VERSION "HSCAN2"

NS_ :

BS_:

BU_: FVCM GW Diagnostics EPS SCSABS Tester

BO_ 1947 DIAG_DTCInfo_FVCM: 7 FVCM
 SG_ DTCInfomationFVCMHSC2 : 7|56@0+ (1,0) [0|0] ""  GW

BO_ 1851 DIAG_PhysResp_FVCM: 8 FVCM
 SG_ DiagnosticRespFVCM : 7|64@0+ (1,0) [0|0] ""  Diagnostics

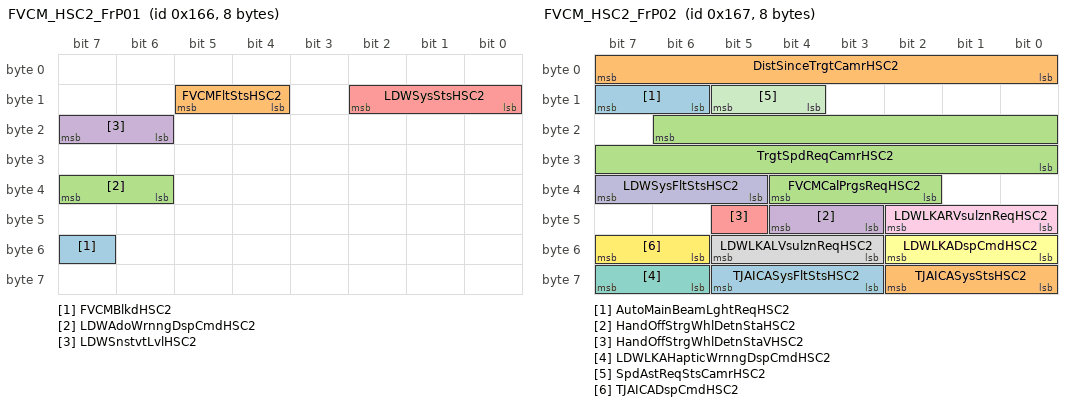
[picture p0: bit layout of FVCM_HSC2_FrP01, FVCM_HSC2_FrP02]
BO_ 358 FVCM_HSC2_FrP01: 8 FVCM
 SG_ FVCMBlkdHSC2 : 55|1@0+ (1,0) [0|1] ""  GW
 SG_ FVCMFltStsHSC2 : 13|2@0+ (1,0) [0|3] ""  GW,EPS
 SG_ LDWAdoWrnngDspCmdHSC2 : 39|2@0+ (1,0) [0|3] ""  GW
 SG_ LDWSnstvtLvlHSC2 : 23|2@0+ (1,0) [0|3] ""  GW
 SG_ LDWSysStsHSC2 : 10|3@0+ (1,0) [0|7] ""  GW

BO_ 359 FVCM_HSC2_FrP02: 8 FVCM
 SG_ AutoMainBeamLghtReqHSC2 : 15|2@0+ (1,0) [0|3] ""  GW
 SG_ DistSinceTrgtCamrHSC2 : 7|8@0+ (8.235,-100) [-100|1999.92] "m"  GW
 SG_ FVCMCalPrgsReqHSC2 : 36|3@0+ (1,0) [0|7] ""  GW
 SG_ HandOffStrgWhlDetnStaHSC2 : 44|2@0+ (1,0) [0|3] ""  GW
 SG_ HandOffStrgWhlDetnStaVHSC2 : 45|1@0+ (1,0) [0|1] ""  GW
 SG_ LDWLKADspCmdHSC2 : 50|3@0+ (1,0) [0|7] ""  GW
 SG_ LDWLKAHapticWrnngDspCmdHSC2 : 63|2@0+ (1,0) [0|3] ""  GW
 SG_ LDWLKALVsulznReqHSC2 : 53|3@0+ (1,0) [0|7] ""  GW
 SG_ LDWLKARVsulznReqHSC2 : 42|3@0+ (1,0) [0|7] ""  GW
 SG_ LDWSysFltStsHSC2 : 39|3@0+ (1,0) [0|7] ""  GW
 SG_ SpdAstReqStsCamrHSC2 : 13|2@0+ (1,0) [0|3] ""  GW
 SG_ TJAICADspCmdHSC2 : 55|2@0+ (1,0) [0|3] ""  GW
 SG_ TJAICASysFltStsHSC2 : 61|3@0+ (1,0) [0|7] ""  GW,EPS
 SG_ TJAICASysStsHSC2 : 58|3@0+ (1,0) [0|7] ""  GW,EPS
 SG_ TrgtSpdReqCamrHSC2 : 22|15@0+ (0.015625,0) [0|511.984] ""  GW

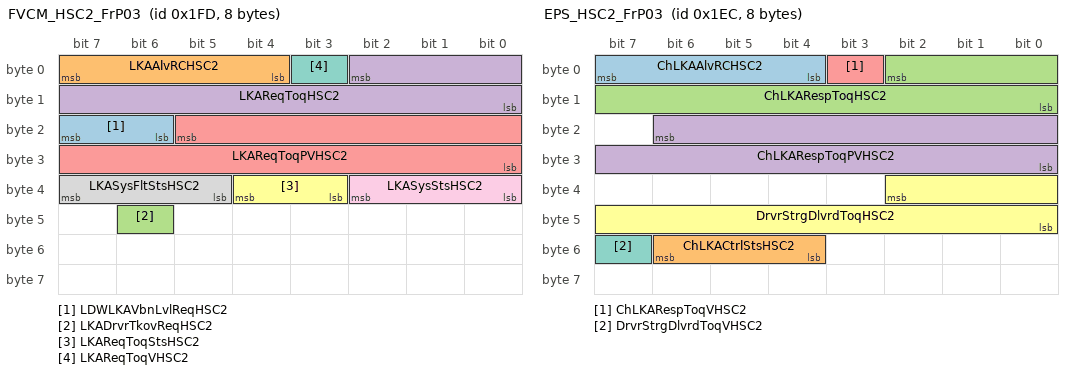
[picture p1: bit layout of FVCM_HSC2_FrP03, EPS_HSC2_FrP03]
BO_ 509 FVCM_HSC2_FrP03: 8 FVCM
 SG_ LDWLKAVbnLvlReqHSC2 : 23|2@0+ (1,0) [0|3] ""  GW,EPS
 SG_ LKAAlvRCHSC2 : 7|4@0+ (1,0) [0|15] ""  EPS
 SG_ LKADrvrTkovReqHSC2 : 46|1@0+ (1,0) [0|1] ""  GW,EPS
 SG_ LKAReqToqHSC2 : 2|11@0+ (0.01,-10.24) [-10.24|10.23] "Nm"  EPS
 SG_ LKAReqToqPVHSC2 : 21|14@0+ (1,0) [0|16383] ""  EPS
 SG_ LKAReqToqStsHSC2 : 36|2@0+ (1,0) [0|3] ""  EPS
 SG_ LKAReqToqVHSC2 : 3|1@0+ (1,0) [0|1] ""  EPS
 SG_ LKASysFltStsHSC2 : 39|3@0+ (1,0) [0|7] ""  GW,EPS
 SG_ LKASysStsHSC2 : 34|3@0+ (1,0) [0|7] ""  GW,EPS

BO_ 2015 DIAG_FuncReq_HSC2: 8 Diagnostics
 SG_ DiagnosticFuncAddrReq_h2 : 7|64@0+ (1,0) [0|0] ""  FVCM

BO_ 1843 DIAG_PhysReq_FVCM: 8 Diagnostics
 SG_ DiagnosticReqFVCM_h2 : 7|64@0+ (1,0) [0|0] ""  FVCM

BO_ 492 EPS_HSC2_FrP03: 8 EPS
 SG_ ChLKAAlvRCHSC2 : 7|4@0+ (1,0) [0|15] ""  FVCM
 SG_ ChLKACtrlStsHSC2 : 54|3@0+ (1,0) [0|7] ""  FVCM
 SG_ ChLKARespToqHSC2 : 2|11@0+ (0.01,-10.24) [-10.24|10.23] "Nm"  FVCM
 SG_ ChLKARespToqPVHSC2 : 22|15@0+ (1,0) [0|32767] ""  FVCM
 SG_ ChLKARespToqVHSC2 : 3|1@0+ (1,0) [0|1] ""  FVCM
 SG_ DrvrStrgDlvrdToqHSC2 : 34|11@0+ (0.01,-10.24) [-10.24|10.23] "Nm"  FVCM
 SG_ DrvrStrgDlvrdToqVHSC2 : 55|1@0+ (1,0) [0|1] ""  FVCM

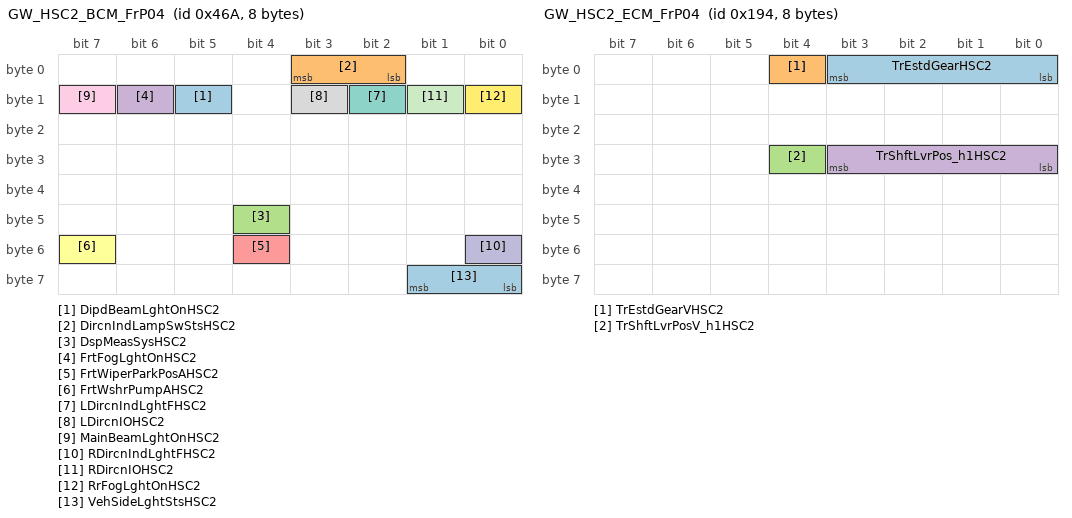
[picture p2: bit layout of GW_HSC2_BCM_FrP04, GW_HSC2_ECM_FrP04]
BO_ 1130 GW_HSC2_BCM_FrP04: 8 GW
 SG_ DipdBeamLghtOnHSC2 : 13|1@0+ (1,0) [0|1] ""  FVCM
 SG_ DircnIndLampSwStsHSC2 : 3|2@0+ (1,0) [0|3] ""  FVCM
 SG_ DspMeasSysHSC2 : 44|1@0+ (1,0) [0|1] ""  FVCM
 SG_ FrtFogLghtOnHSC2 : 14|1@0+ (1,0) [0|1] ""  FVCM
 SG_ FrtWiperParkPosAHSC2 : 52|1@0+ (1,0) [0|1] ""  FVCM
 SG_ FrtWshrPumpAHSC2 : 55|1@0+ (1,0) [0|1] ""  FVCM
 SG_ LDircnIndLghtFHSC2 : 10|1@0+ (1,0) [0|1] ""  FVCM
 SG_ LDircnIOHSC2 : 11|1@0+ (1,0) [0|1] ""  FVCM
 SG_ MainBeamLghtOnHSC2 : 15|1@0+ (1,0) [0|1] ""  FVCM
 SG_ RDircnIndLghtFHSC2 : 48|1@0+ (1,0) [0|1] ""  FVCM
 SG_ RDircnIOHSC2 : 9|1@0+ (1,0) [0|1] ""  FVCM
 SG_ RrFogLghtOnHSC2 : 8|1@0+ (1,0) [0|1] ""  FVCM
 SG_ VehSideLghtStsHSC2 : 57|2@0+ (1,0) [0|3] ""  FVCM

BO_ 540 GW_HSC2_BCM_FrP06: 8 GW
 SG_ ClstrDspdVehSpdHSC2 : 55|8@0+ (1,0) [0|254] "km/h"  FVCM
 SG_ FrtWiperSwStsHSC2 : 47|2@0+ (1,0) [0|3] ""  FVCM

BO_ 498 GW_HSC2_BCM_FrP07: 2 GW
 SG_ SysBPMHSC2 : 5|2@0+ (1,0) [0|3] ""  FVCM
 SG_ SysBPMEnbdHSC2 : 6|1@0+ (1,0) [0|1] ""  FVCM

BO_ 404 GW_HSC2_ECM_FrP04: 8 GW
 SG_ TrEstdGearHSC2 : 3|4@0+ (1,0) [0|15] ""  FVCM
 SG_ TrEstdGearVHSC2 : 4|1@0+ (1,0) [0|1] ""  FVCM
 SG_ TrShftLvrPosV_h1HSC2 : 28|1@0+ (1,0) [0|1] ""  FVCM
 SG_ TrShftLvrPos_h1HSC2 : 27|4@0+ (1,0) [0|15] ""  FVCM

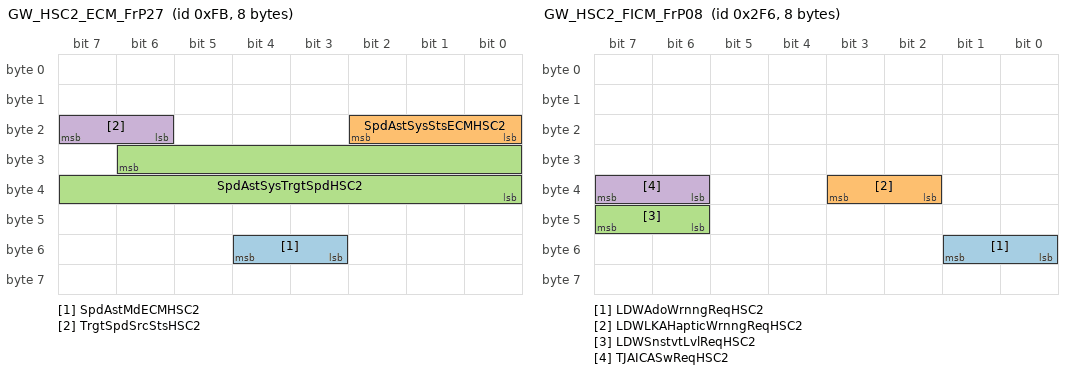
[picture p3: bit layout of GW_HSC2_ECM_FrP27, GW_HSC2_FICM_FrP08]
BO_ 251 GW_HSC2_ECM_FrP27: 8 GW
 SG_ SpdAstMdECMHSC2 : 52|2@0+ (1,0) [0|3] ""  FVCM
 SG_ SpdAstSysStsECMHSC2 : 18|3@0+ (1,0) [0|7] ""  FVCM
 SG_ SpdAstSysTrgtSpdHSC2 : 30|15@0+ (0.015625,0) [0|511.984] ""  FVCM
 SG_ TrgtSpdSrcStsHSC2 : 23|2@0+ (1,0) [0|3] ""  FVCM

BO_ 886 GW_HSC2_FICM_FrP02: 8 GW
 SG_ LDWLKASwReqHSC2 : 31|3@0+ (1,0) [0|7] ""  FVCM
 SG_ RstrFctryDeftsReqHSC2 : 56|1@0+ (1,0) [0|1] ""  FVCM

BO_ 758 GW_HSC2_FICM_FrP08: 8 GW
 SG_ LDWAdoWrnngReqHSC2 : 49|2@0+ (1,0) [0|3] ""  FVCM
 SG_ LDWLKAHapticWrnngReqHSC2 : 35|2@0+ (1,0) [0|3] ""  FVCM
 SG_ LDWSnstvtLvlReqHSC2 : 47|2@0+ (1,0) [0|3] ""  FVCM
 SG_ TJAICASwReqHSC2 : 39|2@0+ (1,0) [0|3] ""  FVCM

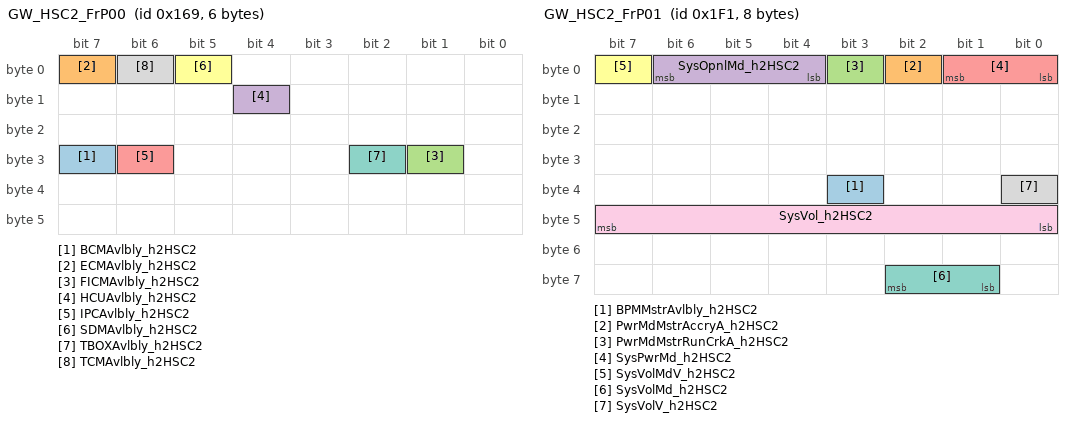
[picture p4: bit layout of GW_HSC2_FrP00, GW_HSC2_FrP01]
BO_ 361 GW_HSC2_FrP00: 6 GW
 SG_ BCMAvlbly_h2HSC2 : 31|1@0+ (1,0) [0|1] ""  FVCM
 SG_ ECMAvlbly_h2HSC2 : 7|1@0+ (1,0) [0|1] ""  FVCM
 SG_ FICMAvlbly_h2HSC2 : 25|1@0+ (1,0) [0|1] ""  FVCM
 SG_ HCUAvlbly_h2HSC2 : 12|1@0+ (1,0) [0|1] ""  FVCM
 SG_ IPCAvlbly_h2HSC2 : 30|1@0+ (1,0) [0|1] ""  FVCM
 SG_ SDMAvlbly_h2HSC2 : 5|1@0+ (1,0) [0|1] ""  FVCM
 SG_ TBOXAvlbly_h2HSC2 : 26|1@0+ (1,0) [0|1] ""  FVCM
 SG_ TCMAvlbly_h2HSC2 : 6|1@0+ (1,0) [0|1] ""  FVCM

BO_ 497 GW_HSC2_FrP01: 8 GW
 SG_ BPMMstrAvlbly_h2HSC2 : 35|1@0+ (1,0) [0|1] ""  FVCM
 SG_ PwrMdMstrAccryA_h2HSC2 : 2|1@0+ (1,0) [0|1] ""  FVCM
 SG_ PwrMdMstrRunCrkA_h2HSC2 : 3|1@0+ (1,0) [0|1] ""  FVCM
 SG_ SysOpnlMd_h2HSC2 : 6|3@0+ (1,0) [0|7] ""  FVCM
 SG_ SysPwrMd_h2HSC2 : 1|2@0+ (1,0) [0|3] ""  FVCM
 SG_ SysVolMdV_h2HSC2 : 7|1@0+ (1,0) [0|1] ""  FVCM
 SG_ SysVolMd_h2HSC2 : 58|2@0+ (1,0) [0|3] ""  FVCM
 SG_ SysVolV_h2HSC2 : 32|1@0+ (1,0) [0|1] ""  FVCM
 SG_ SysVol_h2HSC2 : 47|8@0+ (0.1,3) [3|28.5] "V"  FVCM

BO_ 1344 GW_HSC2_FrP08: 8 GW
 SG_ VehOdoV_h2HSC2 : 31|1@0+ (1,0) [0|1] ""  FVCM
 SG_ VehOdo_h2HSC2 : 7|24@0+ (1,0) [0|16777200] ""  FVCM

BO_ 1009 GW_HSC2_FrP10: 8 GW
 SG_ OtsdAirTemCrValV_h2HSC2 : 48|1@0+ (1,0) [0|1] ""  FVCM
 SG_ OtsdAirTemCrVal_h2HSC2 : 63|8@0+ (0.5,-40) [-40|87.5] "degC"  FVCM

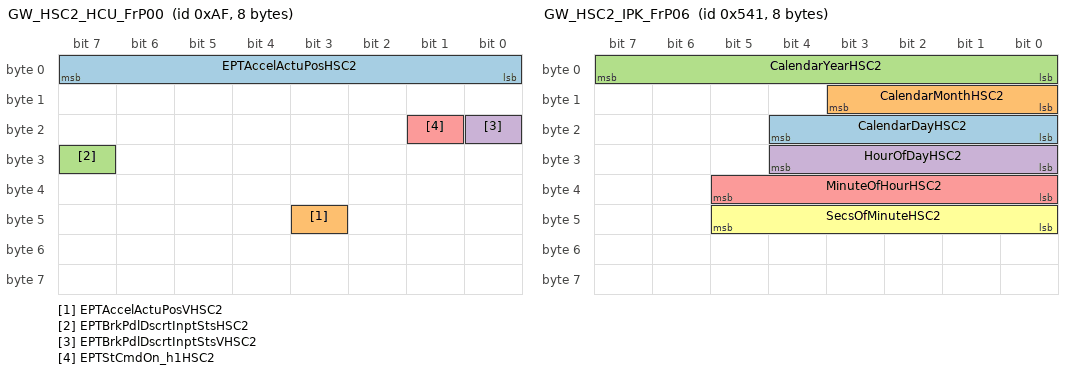
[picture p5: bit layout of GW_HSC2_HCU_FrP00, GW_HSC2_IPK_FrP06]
BO_ 175 GW_HSC2_HCU_FrP00: 8 GW
 SG_ EPTAccelActuPosHSC2 : 7|8@0+ (0.392157,0) [0|100] "%"  FVCM
 SG_ EPTAccelActuPosVHSC2 : 43|1@0+ (1,0) [0|1] ""  FVCM
 SG_ EPTBrkPdlDscrtInptStsHSC2 : 31|1@0+ (1,0) [0|1] ""  FVCM
 SG_ EPTBrkPdlDscrtInptStsVHSC2 : 16|1@0+ (1,0) [0|1] ""  FVCM
 SG_ EPTStCmdOn_h1HSC2 : 17|1@0+ (1,0) [0|1] ""  FVCM

BO_ 406 GW_HSC2_HCU_FrP01: 8 GW
 SG_ EPTAccelEfctvPosHSC2 : 47|8@0+ (0.392157,0) [0|100] "%"  FVCM
 SG_ EPTRdy_h1HSC2 : 38|1@0+ (1,0) [0|1] ""  FVCM

BO_ 1345 GW_HSC2_IPK_FrP06: 8 GW
 SG_ CalendarDayHSC2 : 20|5@0+ (1,0) [0|31] "days"  FVCM
 SG_ CalendarMonthHSC2 : 11|4@0+ (1,0) [0|15] ""  FVCM
 SG_ CalendarYearHSC2 : 7|8@0+ (1,2000) [2000|2255] "year"  FVCM
 SG_ HourOfDayHSC2 : 28|5@0+ (1,0) [0|23] ""  FVCM
 SG_ MinuteOfHourHSC2 : 37|6@0+ (1,0) [0|59] ""  FVCM
 SG_ SecsOfMinuteHSC2 : 45|6@0+ (1,0) [0|59] ""  FVCM

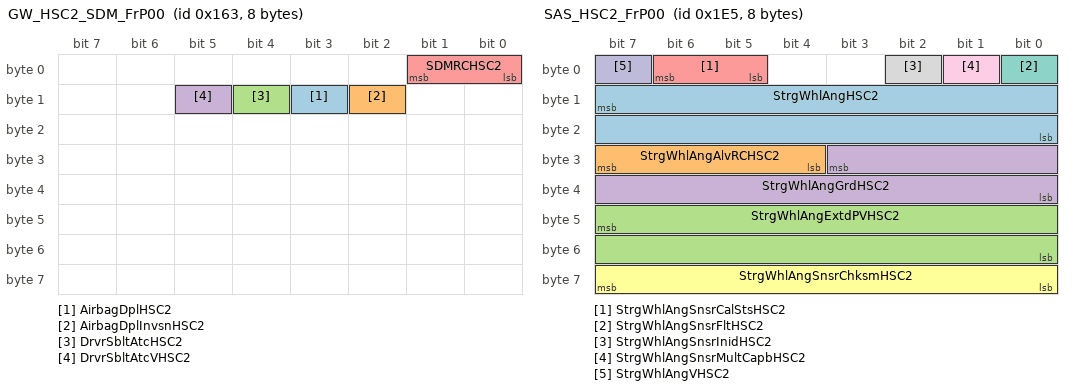
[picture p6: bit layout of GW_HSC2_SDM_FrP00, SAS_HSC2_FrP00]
BO_ 355 GW_HSC2_SDM_FrP00: 8 GW
 SG_ AirbagDplHSC2 : 11|1@0+ (1,0) [0|1] ""  FVCM
 SG_ AirbagDplInvsnHSC2 : 10|1@0+ (1,0) [0|1] ""  FVCM
 SG_ DrvrSbltAtcHSC2 : 12|1@0+ (1,0) [0|1] ""  FVCM
 SG_ DrvrSbltAtcVHSC2 : 13|1@0+ (1,0) [0|1] ""  FVCM
 SG_ SDMRCHSC2 : 1|2@0+ (1,0) [0|3] ""  FVCM

BO_ 485 SAS_HSC2_FrP00: 8 EPS
 SG_ StrgWhlAngHSC2 : 15|16@0+ (0.0625,-2048) [-2048|2047.88] "degree"  FVCM
 SG_ StrgWhlAngAlvRCHSC2 : 31|4@0+ (1,0) [0|15] ""  FVCM
 SG_ StrgWhlAngExtdPVHSC2 : 47|16@0+ (1,0) [0|65535] ""  FVCM
 SG_ StrgWhlAngGrdHSC2 : 27|12@0+ (1,-2048) [-2048|2046] "degree/s"  FVCM
 SG_ StrgWhlAngSnsrCalStsHSC2 : 6|2@0+ (1,0) [0|3] ""  FVCM
 SG_ StrgWhlAngSnsrChksmHSC2 : 63|8@0+ (1,0) [0|255] ""  FVCM
 SG_ StrgWhlAngSnsrFltHSC2 : 0|1@0+ (1,0) [0|1] ""  FVCM
 SG_ StrgWhlAngSnsrInidHSC2 : 2|1@0+ (1,0) [0|1] ""  FVCM
 SG_ StrgWhlAngSnsrMultCapbHSC2 : 1|1@0+ (1,0) [0|1] ""  FVCM
 SG_ StrgWhlAngVHSC2 : 7|1@0+ (1,0) [0|1] ""  FVCM

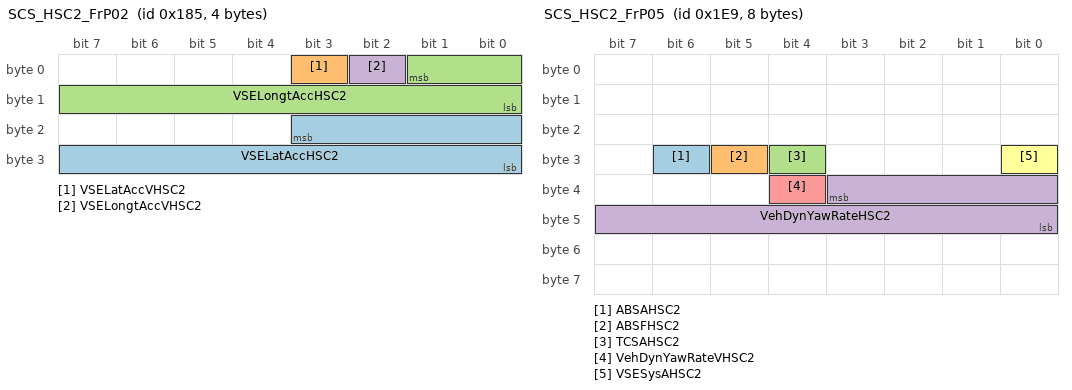
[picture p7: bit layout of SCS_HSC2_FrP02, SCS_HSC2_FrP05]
BO_ 389 SCS_HSC2_FrP02: 4 SCSABS
 SG_ VSELatAccHSC2 : 19|12@0- (0.015625,0) [-32|31.9844] "m/s^2"  FVCM
 SG_ VSELatAccVHSC2 : 3|1@0+ (1,0) [0|1] ""  FVCM
 SG_ VSELongtAccHSC2 : 1|10@0- (0.03,0) [-15.36|15.33] "m/s^2"  FVCM
 SG_ VSELongtAccVHSC2 : 2|1@0+ (1,0) [0|1] ""  FVCM

BO_ 455 SCS_HSC2_FrP03: 8 SCSABS
 SG_ LNonDrvnWhlRotlDircnHSC2 : 33|2@0+ (1,0) [0|3] ""  FVCM
 SG_ RNonDrvnWhlRotlDircnHSC2 : 35|2@0+ (1,0) [0|3] ""  FVCM

BO_ 489 SCS_HSC2_FrP05: 8 SCSABS
 SG_ ABSAHSC2 : 30|1@0+ (1,0) [0|1] ""  FVCM
 SG_ ABSFHSC2 : 29|1@0+ (1,0) [0|1] ""  FVCM
 SG_ TCSAHSC2 : 28|1@0+ (1,0) [0|1] ""  FVCM
 SG_ VehDynYawRateHSC2 : 35|12@0- (0.0625,0) [-128|127.938] "deg/s"  FVCM
 SG_ VehDynYawRateVHSC2 : 36|1@0+ (1,0) [0|1] ""  FVCM
 SG_ VSESysAHSC2 : 24|1@0+ (1,0) [0|1] ""  FVCM

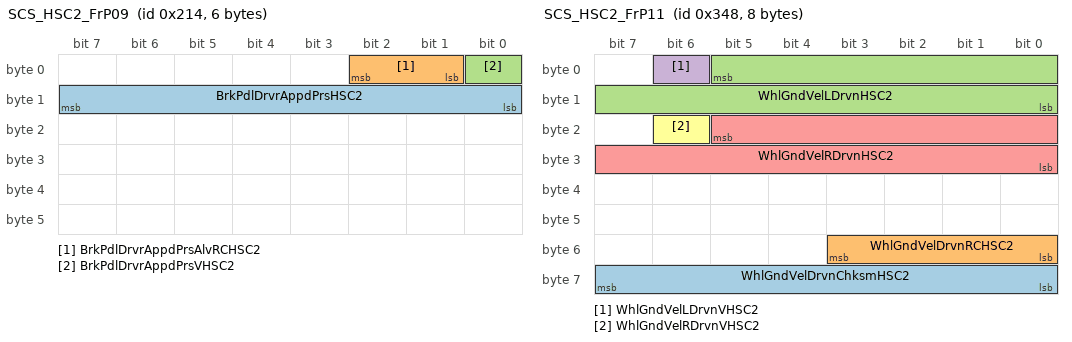
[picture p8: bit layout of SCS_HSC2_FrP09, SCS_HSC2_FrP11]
BO_ 532 SCS_HSC2_FrP09: 6 SCSABS
 SG_ BrkPdlDrvrAppdPrsHSC2 : 15|8@0+ (75,0) [0|19125] "kPa"  FVCM
 SG_ BrkPdlDrvrAppdPrsAlvRCHSC2 : 2|2@0+ (1,0) [0|3] ""  FVCM
 SG_ BrkPdlDrvrAppdPrsVHSC2 : 0|1@0+ (1,0) [0|1] ""  FVCM

BO_ 840 SCS_HSC2_FrP11: 8 SCSABS
 SG_ WhlGndVelDrvnChksmHSC2 : 63|8@0+ (1,0) [0|255] ""  FVCM
 SG_ WhlGndVelDrvnRCHSC2 : 51|4@0+ (1,0) [0|15] ""  FVCM
 SG_ WhlGndVelLDrvnHSC2 : 5|14@0+ (0.03125,0) [0|511.969] "km/h"  FVCM
 SG_ WhlGndVelLDrvnVHSC2 : 6|1@0+ (1,0) [0|1] ""  FVCM
 SG_ WhlGndVelRDrvnHSC2 : 21|14@0+ (0.03125,0) [0|511.969] "km/h"  FVCM
 SG_ WhlGndVelRDrvnVHSC2 : 22|1@0+ (1,0) [0|1] ""  FVCM

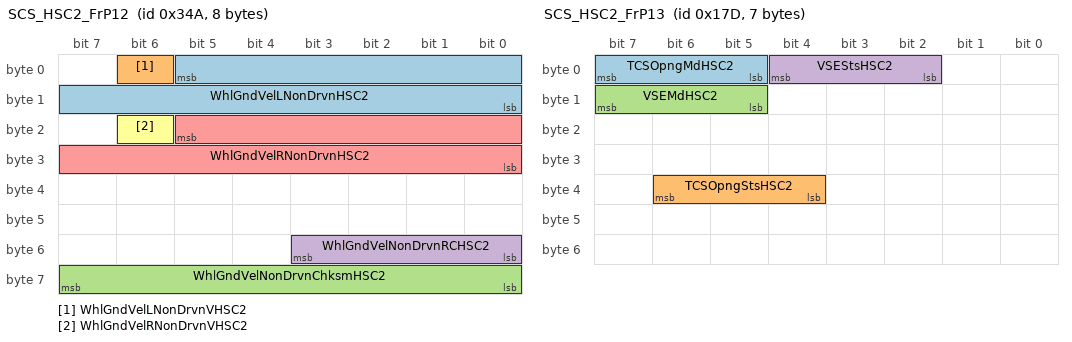
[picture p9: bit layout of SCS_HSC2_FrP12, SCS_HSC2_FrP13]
BO_ 842 SCS_HSC2_FrP12: 8 SCSABS
 SG_ WhlGndVelLNonDrvnHSC2 : 5|14@0+ (0.03125,0) [0|511.969] "km/h"  FVCM
 SG_ WhlGndVelLNonDrvnVHSC2 : 6|1@0+ (1,0) [0|1] ""  FVCM
 SG_ WhlGndVelNonDrvnChksmHSC2 : 63|8@0+ (1,0) [0|255] ""  FVCM
 SG_ WhlGndVelNonDrvnRCHSC2 : 51|4@0+ (1,0) [0|15] ""  FVCM
 SG_ WhlGndVelRNonDrvnHSC2 : 21|14@0+ (0.03125,0) [0|511.969] "km/h"  FVCM
 SG_ WhlGndVelRNonDrvnVHSC2 : 22|1@0+ (1,0) [0|1] ""  FVCM

BO_ 381 SCS_HSC2_FrP13: 7 SCSABS
 SG_ TCSOpngMdHSC2 : 7|3@0+ (1,0) [0|7] ""  FVCM
 SG_ TCSOpngStsHSC2 : 38|3@0+ (1,0) [0|7] ""  FVCM
 SG_ VSEMdHSC2 : 15|3@0+ (1,0) [0|7] ""  FVCM
 SG_ VSEStsHSC2 : 4|3@0+ (1,0) [0|7] ""  FVCM

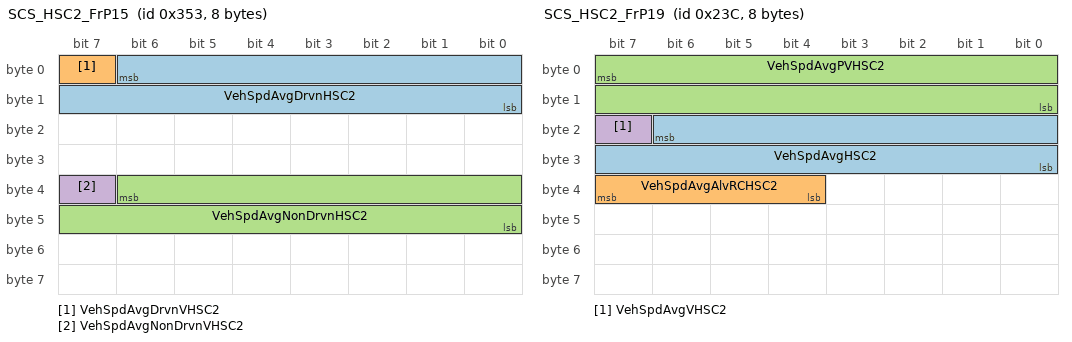
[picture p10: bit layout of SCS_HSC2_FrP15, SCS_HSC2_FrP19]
BO_ 851 SCS_HSC2_FrP15: 8 SCSABS
 SG_ VehSpdAvgDrvnHSC2 : 6|15@0+ (0.015625,0) [0|511.984] "km/h"  FVCM
 SG_ VehSpdAvgDrvnVHSC2 : 7|1@0+ (1,0) [0|1] ""  FVCM
 SG_ VehSpdAvgNonDrvnHSC2 : 38|15@0+ (0.015625,0) [0|511.984] "km/h"  FVCM
 SG_ VehSpdAvgNonDrvnVHSC2 : 39|1@0+ (1,0) [0|1] ""  FVCM

BO_ 572 SCS_HSC2_FrP19: 8 SCSABS
 SG_ VehSpdAvgHSC2 : 22|15@0+ (0.015625,0) [0|511.984] "km/h"  FVCM
 SG_ VehSpdAvgAlvRCHSC2 : 39|4@0+ (1,0) [0|15] ""  FVCM
 SG_ VehSpdAvgPVHSC2 : 7|16@0+ (1,0) [0|65535] ""  FVCM
 SG_ VehSpdAvgVHSC2 : 23|1@0+ (1,0) [0|1] ""  FVCM

BO_ 588 SCS_HSC2_FrP22: 8 SCSABS
 SG_ LDrvnWhlRotlDircnHSC2 : 15|2@0+ (1,0) [0|3] ""  FVCM
 SG_ RDrvnWhlRotlDircnHSC2 : 2|2@0+ (1,0) [0|3] ""  FVCM

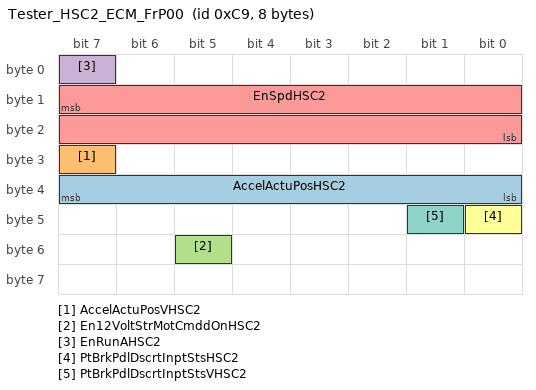
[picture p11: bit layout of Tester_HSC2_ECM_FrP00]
BO_ 201 Tester_HSC2_ECM_FrP00: 8 Tester
 SG_ AccelActuPosHSC2 : 39|8@0+ (0.392157,0) [0|100] "%"  FVCM
 SG_ AccelActuPosVHSC2 : 31|1@0+ (1,0) [0|1] ""  FVCM
 SG_ En12VoltStrMotCmddOnHSC2 : 53|1@0+ (1,0) [0|1] ""  FVCM
 SG_ EnRunAHSC2 : 7|1@0+ (1,0) [0|1] ""  FVCM
 SG_ EnSpdHSC2 : 15|16@0+ (0.25,0) [0|16383.8] "rpm"  FVCM
 SG_ PtBrkPdlDscrtInptStsHSC2 : 40|1@0+ (1,0) [0|1] ""  FVCM
 SG_ PtBrkPdlDscrtInptStsVHSC2 : 41|1@0+ (1,0) [0|1] ""  FVCM

BO_ 190 Tester_HSC2_ECM_FrP01: 3 Tester
 SG_ AccelEfctvPosHSC2 : 23|8@0+ (0.392157,0) [0|100] "%"  FVCM

BO_ 471 Tester_HSC2_ECM_FrP07: 2 Tester
 SG_ EnASSStaHSC2 : 1|2@0+ (1,0) [0|3] ""  FVCM
